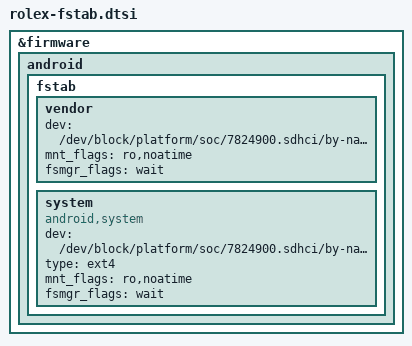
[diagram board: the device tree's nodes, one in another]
&firmware {
	android {
		/delete-node/ vbmeta;
		fstab {
			vendor {
				dev = "/dev/block/platform/soc/7824900.sdhci/by-name/cust";
				mnt_flags = "ro,noatime";
				fsmgr_flags = "wait";
				status = "ok";
			};

			system {
				compatible = "android,system";
				dev = "/dev/block/platform/soc/7824900.sdhci/by-name/system";
				type = "ext4";
				mnt_flags = "ro,noatime";
				fsmgr_flags = "wait";
				status = "ok";
			};
		};
	};
};
